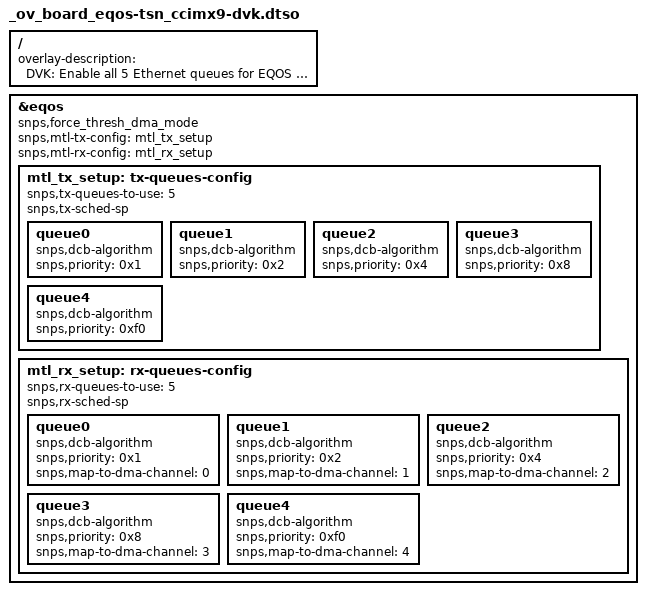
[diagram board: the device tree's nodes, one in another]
/*
 * Copyright 2024 Digi International Inc.
 *
 * Permission to use, copy, modify, and/or distribute this software for any
 * purpose with or without fee is hereby granted, provided that the above
 * copyright notice and this permission notice appear in all copies.
 * THE SOFTWARE IS PROVIDED "AS IS" AND THE AUTHOR DISCLAIMS ALL WARRANTIES
 * WITH REGARD TO THIS SOFTWARE INCLUDING ALL IMPLIED WARRANTIES OF
 * MERCHANTABILITY AND FITNESS. IN NO EVENT SHALL THE AUTHOR BE LIABLE FOR
 * ANY SPECIAL, DIRECT, INDIRECT, OR CONSEQUENTIAL DAMAGES OR ANY DAMAGES
 * WHATSOEVER RESULTING FROM LOSS OF USE, DATA OR PROFITS, WHETHER IN AN
 * ACTION OF CONTRACT, NEGLIGENCE OR OTHER TORTIOUS ACTION, ARISING OUT OF
 * OR IN CONNECTION WITH THE USE OR PERFORMANCE OF THIS SOFTWARE.
 */

/dts-v1/;
/plugin/;

/ {
	fragment@0 {
		target-path = "/";
		__overlay__ {
			overlay-description = "DVK: Enable all 5 Ethernet queues for EQOS controller";
		};
	};

	/* Add Eqos TX and RX queues */
	fragment@1 {
		target = <&eqos>;
		__overlay__ {
			snps,force_thresh_dma_mode;
			snps,mtl-tx-config = <&mtl_tx_setup>;
			snps,mtl-rx-config = <&mtl_rx_setup>;

			mtl_tx_setup: tx-queues-config {
		                snps,tx-queues-to-use = <5>;
				snps,tx-sched-sp;

				queue0 {
					snps,dcb-algorithm;
					snps,priority = <0x1>;
				};

				queue1 {
					snps,dcb-algorithm;
					snps,priority = <0x2>;
				};

				queue2 {
					snps,dcb-algorithm;
					snps,priority = <0x4>;
				};

				queue3 {
					snps,dcb-algorithm;
					snps,priority = <0x8>;
				};

				queue4 {
					snps,dcb-algorithm;
					snps,priority = <0xf0>;
				};
			};

			mtl_rx_setup: rx-queues-config {
				snps,rx-queues-to-use = <5>;
				snps,rx-sched-sp;

				queue0 {
					snps,dcb-algorithm;
					snps,priority = <0x1>;
					snps,map-to-dma-channel = <0>;
				};

				queue1 {
					snps,dcb-algorithm;
					snps,priority = <0x2>;
					snps,map-to-dma-channel = <1>;
				};

				queue2 {
					snps,dcb-algorithm;
					snps,priority = <0x4>;
					snps,map-to-dma-channel = <2>;
				};

				queue3 {
					snps,dcb-algorithm;
					snps,priority = <0x8>;
					snps,map-to-dma-channel = <3>;
				};

				queue4 {
					snps,dcb-algorithm;
					snps,priority = <0xf0>;
					snps,map-to-dma-channel = <4>;
				};
			};
		};
	};
};
